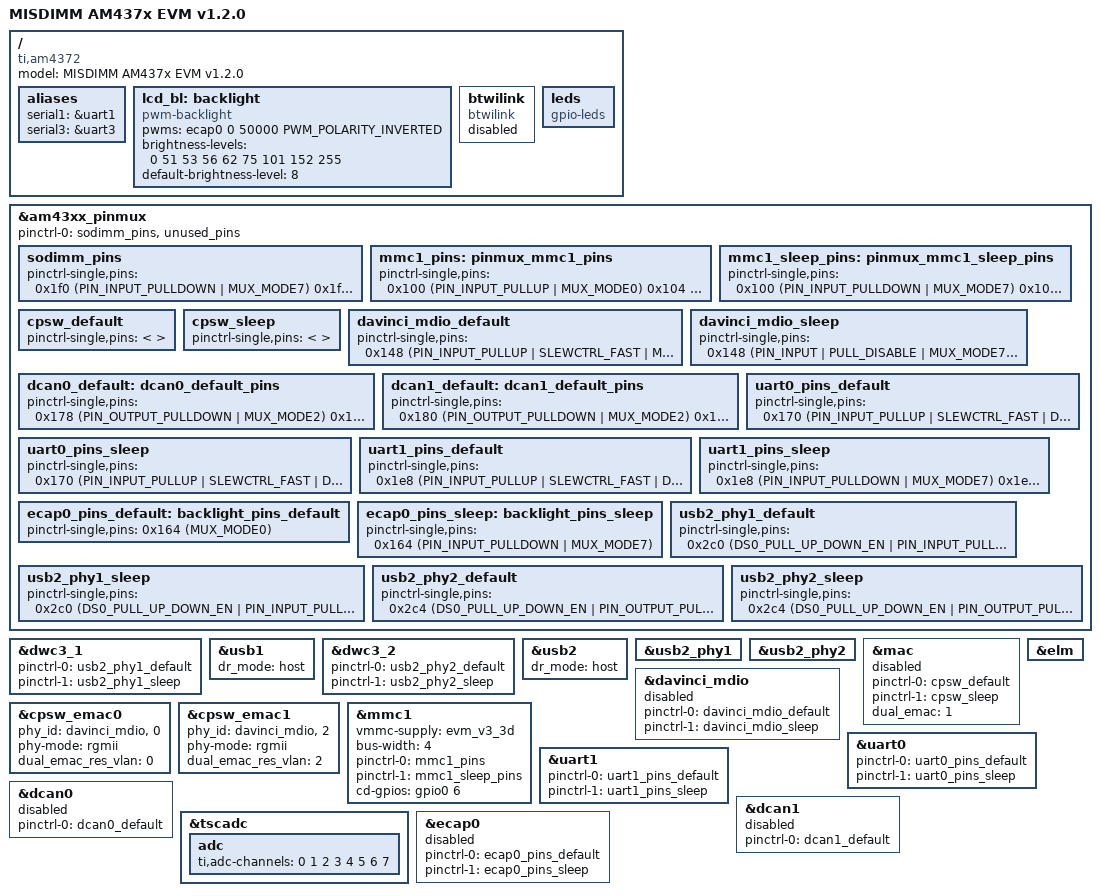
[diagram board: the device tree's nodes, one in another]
/*
 * MIS www.mistec.de SO-DIMM System on Module Evalboard with TI am437x
 * Copyright (C) 2015 - http://www.mistec.de Robert Woerle
 * 
 * Copied from arch/arm/boot/dts/am437x-gp-evm.dts which has
 * Copyright (C) 2013 Texas Instruments Incorporated - http://www.ti.com/
 * 
 * This program is free software; you can redistribute it and/or modify
 * it under the terms of the GNU General Public License version 2 as
 * published by the Free Software Foundation.
 */

/* AM437x SOM EVM Mistec */

/dts-v1/;

#include "am437x-misdimm.dtsi"
#include <dt-bindings/pinctrl/am43xx.h>
#include <dt-bindings/pwm/pwm.h>
#include <dt-bindings/interrupt-controller/irq.h>

/ {
	model = "MISDIMM AM437x EVM v1.2.0";
	compatible = "ti,am4372","ti,am43";

	aliases {
		serial1 = &uart1;
		serial3 = &uart3;
	};

	lcd_bl: backlight {
		compatible = "pwm-backlight";
		pwms = <&ecap0 0 50000 PWM_POLARITY_INVERTED>;
		brightness-levels = <0 51 53 56 62 75 101 152 255>;
		default-brightness-level = <8>;
	};

 	btwilink {
		status = "disabled";
 		compatible = "btwilink";
 	};

	leds {
		compatible = "gpio-leds";

		/* 0x274 P600_138 C24 xdma_event_intr1.gpio0_20 */
/*		led_cpu0 {
			label = "misdimm-evm_usr0";
			gpios = <&gpio0 20 GPIO_ACTIVE_HIGH>;
			linux,default-trigger = "cpu0";
		};*/

		/*0x238 P600_140 D25 gpio5_8.gpio5_8 */
/*		led_mmc0 {
			label = "misdimm-evm_usr1";
			gpios = <&gpio5 8 GPIO_ACTIVE_HIGH>;
			linux,default-trigger = "mmc0";
		};*/

		/* 0x23c P600_142 F24 gpio5_9.gpio5_9 */
/*		led_mmc1 {
			label = "misdimm-evm_usr2";
			gpios = <&gpio5 9 GPIO_ACTIVE_HIGH>;
			linux,default-trigger = "mmc1";
		};*/
	};
};

&am43xx_pinmux {
	pinctrl-names = "default";
	pinctrl-0 = <&sodimm_pins &unused_pins>;


	sodimm_pins: sodimm_pins {
		pinctrl-single,pins = <

			/* ClassName ADC01 */
			/* P600_25 AA12 ADC0_AIN0 */
			/* P600_27 Y12  ADC0_AIN1 */
			/* P600_29 Y13  ADC0_AIN2 */
			/* P600_31 AA13 ADC0_AIN3 */
			/* P600_33 AB13 ADC0_AIN4 */
			/* P600_35 AC13 ADC0_AIN5 */
			/* P600_37 AD13 ADC0_AIN6 */
			/* P600_39 AE13 ADC0_AIN7 */

			/* P600_26 AC16 ADC1_AIN0 */
			/* P600_28 AB16 ADC1_AIN1 */
			/* P600_30 AA16 ADC1_AIN2 */
			/* P600_32 AB15 ADC1_AIN3 */
			/* P600_34 AA15 ADC1_AIN4 */
			/* P600_36 Y15  ADC1_AIN5 */
			/* P600_38 AE16 ADC1_AIN6 */
			/* P600_40 AD16 ADC1_AIN7 */


			/* ClassName: UART0123 */
			0x1f0 (PIN_INPUT_PULLDOWN | MUX_MODE7) /* P600_50 AD21 cam1_data2.gpio4_16 */
			0x1f4 (PIN_INPUT_PULLDOWN | MUX_MODE7) /* P600_48 AE22 cam1_data3.gpio4_17 */
			0x1f8 (PIN_INPUT_PULLDOWN | MUX_MODE7) /* P600_43 AD22 cam1_data4.gpio4_18 */
			0x1fc (PIN_INPUT_PULLDOWN | MUX_MODE7) /* P600_45 AE23 cam1_data5.gpio4_19 */
			0x200 (PIN_INPUT_PULLDOWN | MUX_MODE7) /* P600_49 AD23 cam1_data6.gpio4_20 */
			0x204 (PIN_INPUT_PULLDOWN | MUX_MODE7) /* P600_47 AE24 cam1_data7.gpio4_21 */

			0x228 (PIN_INPUT_PULLDOWN | MUX_MODE7)	/* P600_55 H25 uart3_rxd.uart3_rxd */
			0x22c (PIN_INPUT_PULLDOWN | MUX_MODE7)	/* P600_53 H24 uart3_txd.uart3_txd */
			0x230 (PIN_INPUT_PULLDOWN | MUX_MODE7)	/* P600_59 H22 uart3_ctsn.uart3_ctsn */
			0x234 (PIN_INPUT_PULLDOWN | MUX_MODE7)	/* P600_57 K24 uart3_rtsn.uart3_rtsn */


			/* ClassName:LCD */
			0x0a0 (PIN_OUTPUT_PULLDOWN | MUX_MODE5) /* P600_77  B22 dss_data0.gpio2_6 */
			0x0a4 (PIN_INPUT_PULLDOWN | MUX_MODE7) /* P600_78  A21 dss_data1.gpio2_7 */
			0x0a8 (PIN_INPUT_PULLDOWN | MUX_MODE7) /* P600_79  B21 dss_data2.gpio2_8 */
			0x0ac (PIN_INPUT_PULLDOWN | MUX_MODE7) /* P600_80  C21 dss_data3.gpio2_9 */
			0x0b0 (PIN_INPUT_PULLDOWN | MUX_MODE7) /* P600_81  A20 dss_data4.gpio2_10 */
			0x0b4 (PIN_INPUT_PULLDOWN | MUX_MODE7) /* P600_82  B20 dss_data5.gpio2_11 */
			0x0b8 (PIN_INPUT_PULLDOWN | MUX_MODE7) /* P600_83  C20 dss_data6.gpio2_12 */
			0x0bc (PIN_INPUT_PULLDOWN | MUX_MODE7) /* P600_84  E19 dss_data7.gpio2_13 */
			0x0c0 (PIN_INPUT_PULLDOWN | MUX_MODE7) /* P600_85  A19 dss_data8.gpio2_14 */
			0x0c4 (PIN_INPUT_PULLDOWN | MUX_MODE7) /* P600_86  B19 dss_data9.gpio2_15 */
			0x0c8 (PIN_INPUT_PULLDOWN | MUX_MODE7) /* P600_87  A18 dss_data10.gpio2_16 */
			0x0cc (PIN_INPUT_PULLDOWN | MUX_MODE7) /* P600_88  B18 dss_data11.gpio2_17 */
			0x0d0 (PIN_INPUT_PULLDOWN | MUX_MODE7) /* P600_89  C19 dss_data12.gpio0_8 */
			0x0d4 (PIN_INPUT_PULLDOWN | MUX_MODE7) /* P600_90  D19 dss_data13.gpio0_9 */
			0x0d8 (PIN_INPUT_PULLDOWN | MUX_MODE7) /* P600_91  C17 dss_data14.gpio0_10 */
			0x0dc (PIN_INPUT_PULLDOWN | MUX_MODE7) /* P600_92  D17 dss_data15.gpio0_11 */

			0x0e0 (PIN_INPUT_PULLDOWN | MUX_MODE7) /* P600_74  B23 dss_vsync.gpio2_22 */
			0x0e4 (PIN_INPUT_PULLDOWN | MUX_MODE7) /* P600_75  A23 dss_hsync.gpio2_23 */
			0x0e8 (PIN_INPUT_PULLDOWN | MUX_MODE7) /* P600_76  A22 dss_pclk.gpio2_24 */
			0x0ec (PIN_INPUT_PULLDOWN | MUX_MODE7) /* P600_73  A24 dss_acbias.gpio2_25 */

			0x148 (PIN_INPUT | PULL_DISABLE | MUX_MODE7) /* P600_103 + P600_137 A17 mdio_data.gpio0_0 */
			0x14c (PIN_INPUT | PULL_DISABLE | MUX_MODE7) /* P600_105 + P600_139 B17 mdio_clk.gpio0_1 */

			0x1b0 (PIN_INPUT_PULLDOWN | MUX_MODE7) /* P600_100 AE17 cam0_hd.gpio4_0 */
			0x1b4 (PIN_INPUT_PULLDOWN | MUX_MODE7) /* P600_99  AD18 cam0_vd.gio4_1 */
			0x1b8 (PIN_INPUT_PULLDOWN | MUX_MODE7) /* P600_98  AC18 cam0_field.gpio4_2 */
			0x1bc (PIN_INPUT_PULLDOWN | MUX_MODE7) /* P600_97  AD17 cam0_wen.gpio4_3 */
			0x1c0 (PIN_INPUT_PULLDOWN | MUX_MODE7) /* P600_96  AC20 can0_pclk.gpio4_4 */
			0x1c4 (PIN_INPUT_PULLDOWN | MUX_MODE7) /* P600_95  AB19 cam0_data8.gpio4_5 */
			0x1c8 (PIN_INPUT_PULLDOWN | MUX_MODE7) /* P600_94  AA19 cam0_data9.gpio4_6 */
			0x1cc (PIN_INPUT_PULLDOWN | MUX_MODE7) /* P600_93  AC24 cam1_data9.gpio4_7 */

			/* ClassName:SPI */
			0x190 (PIN_INPUT_PULLDOWN | MUX_MODE7) /* P600_106 N24  mcasp0_aclkx.gpio3_14 */
			0x194 (PIN_INPUT_PULLDOWN | MUX_MODE7) /* P600_108 N22  mcasp0_fsx.gpio3_15 */
			0x198 (PIN_INPUT_PULLDOWN | MUX_MODE7) /* P600_110 H23  mcasp0_axr0.gpio3_16 */
			0x19c (PIN_INPUT_PULLDOWN | MUX_MODE7) /* P600_112 M24  mcasp0_ahclkr.gpio3_17 */
			0x1d8 (PIN_INPUT_PULLDOWN | MUX_MODE7) /* P600_114 AC23 cam1_vd.gpio4_10 */
			0x1dc (PIN_INPUT_PULLDOWN | MUX_MODE7) /* P600_116 AE21 cam1_pclk.gpio4_11 */


			/* ClassName:AUDIO */
			0x144 (PIN_INPUT_PULLDOWN | MUX_MODE7) /* P600_120 A16  rmii1_ref_clk.gpio0_29 */
			0x108 (PIN_INPUT_PULLDOWN | MUX_MODE7) /* P600_122 D16  mii1_col.gpio3_0 */
			0x10c (PIN_INPUT_PULLDOWN | MUX_MODE7) /* P600_126 B14  mii1_crs.gpio3_1 */
			0x110 (PIN_INPUT_PULLDOWN | MUX_MODE7) /* P600_128 B13  mii1_rx_er.gpio3_2 */
			0x270 (PIN_INPUT_PULLDOWN | MUX_MODE7) /* P600_124 D24  xdma_event_intr0.gpio0_19 */


			/* ClassName:GPIOS */
			0x070 (PIN_INPUT_PULLDOWN | MUX_MODE7) /* P600_178 A2   gpmc_wait0.gpio0_30 */
			0x074 (PIN_INPUT_PULLDOWN | MUX_MODE7) /* P600_150 B3   gpmc_wpn.gpio0_31 */
			0x078 (PIN_INPUT_PULLDOWN | MUX_MODE7) /* P600_152 A3   gpmc_be1n.gpio1_28 */
			0x07c (PIN_INPUT_PULLDOWN | MUX_MODE7) /* P600_146 A8   gpmc_csn0.gpio1_29 */
			0x090 (PIN_INPUT_PULLDOWN | MUX_MODE7) /* P600_144 A9   gpmc_advn_ale.gpio2_2 */
			0x09c (PIN_INPUT_PULLDOWN | MUX_MODE7) /* P600_156 C10  gpmc_be0n_cle.gpio2_5 */
			0x150 (PIN_INPUT_PULLDOWN | MUX_MODE7) /* P600_160 P23  spi0_sclk.gpio0_2 */
			0x154 (PIN_INPUT_PULLDOWN | MUX_MODE7) /* P600_154 T22  spi0_d0.gpio0_3 */
			0x1a0 (PIN_INPUT_PULLDOWN | MUX_MODE7) /* P600_180 L23  mcasp0_aclkr.gpio3_18 */
			0x1a4 (PIN_INPUT_PULLDOWN | MUX_MODE7) /* P600_176 K23  mcasp0_fsr.gpio3_19 */
			0x1ac (PIN_INPUT_PULLDOWN | MUX_MODE7) /* P600_162 L24  mcasp0_ahclkx.gpio3_21 */
			0x1e0 (PIN_INPUT_PULLDOWN | MUX_MODE7) /* P600_184 AC25 cam1_field.gpio4_12 */
			0x1e4 (PIN_INPUT_PULLDOWN | MUX_MODE7) /* P600_182 AB25 cam1_wen.gpio4_13 */
			0x218 (PIN_INPUT_PULLDOWN | MUX_MODE7) /* P600_148 AE19 cam0_data4.gpio4_26 */
			0x220 (PIN_INPUT_PULLDOWN | MUX_MODE7) /* P600_174 AE20 cam0_data6.gpio4_28 */
			0x224 (PIN_INPUT_PULLDOWN | MUX_MODE7) /* P600_186 AD20 cam0_data7.gpio4_29 */
			0x240 (PIN_INPUT_PULLDOWN | MUX_MODE7) /* P600_170 G20  gpio5_10.gpio5_10 */
			0x250 (PIN_INPUT_PULLDOWN | MUX_MODE7) /* P600_172 P25  spi4_sclk.gpio5_4 */
			0x258 (PIN_INPUT_PULLDOWN | MUX_MODE7) /* P600_164 P24  spi4_d1.gpio5_6 */
			0x264 (PIN_INPUT_PULLDOWN | MUX_MODE7) /* P600_158 P22  spi2_d0.gpio3_22 */
			0x278 (PIN_INPUT_PULLDOWN | MUX_MODE7) /* P600_166 H20  clkreq.gpio0_24 */

			/* ClassName:ETH1 Slave 1 */
			0x114 (PIN_INPUT_PULLDOWN | MUX_MODE7)			/* P600_119 A13 mii1_txen.gpio3_3 */
			0x118 (PIN_INPUT_PULLDOWN | MUX_MODE7)			/* P600_109 A15 mii1_rxdv.gpio3_4 */
			0x11c (PIN_INPUT_PULLDOWN | MUX_MODE7)			/* P600_123 C16 mii1_txd3.gpio0_16 */
			0x120 (PIN_INPUT_PULLDOWN | MUX_MODE7)			/* P600_125 C13 mii1_txd2.gpio0_17 */
			0x124 (PIN_INPUT_PULLDOWN | MUX_MODE7)			/* P600_127 A14 mii1_txd1.gpio0_21 */
			0x128 (PIN_INPUT_PULLDOWN | MUX_MODE7)			/* P600_129 B15 mii1_txd0.gpio0_28 */
			0x12c (PIN_INPUT_PULLDOWN | MUX_MODE7)			/* P600_121 D14 mii1_txclk.gpio3_9 */
			0x130 (PIN_INPUT_PULLDOWN | MUX_MODE7)			/* P600_107 D13 mii1_rxclk.gpio3_10 */
			0x134 (PIN_INPUT | PULL_DISABLE | MUX_MODE7)	/* P600_117 C14 mii1_rxd3.gpio2_18 */
			0x138 (PIN_INPUT | PULL_DISABLE | MUX_MODE7)	/* P600_115 E16 mii1_rxd2.gpio2_19 */
			0x13c (PIN_INPUT | PULL_DISABLE | MUX_MODE7)	/* P600_113 B16 mii1_rxd1.gpio2_20 */
			0x140 (PIN_INPUT | PULL_DISABLE | MUX_MODE7)	/* P600_111 F17 mii1_rxd0.gpio2_21 */
			0x16C (PIN_INPUT_PULLDOWN | MUX_MODE7)			/* P600_58 J25 uart0_rtsn.gpio1_9 */

			/* ClassName:ETH2 Slave 2 */
			0x040 (PIN_INPUT_PULLDOWN | MUX_MODE7)			/* P600_153 C3 gpmc_a0.gpio1_16 */
			0x044 (PIN_INPUT_PULLDOWN | MUX_MODE7)			/* P600_143 C5 gpmc_a1.gpio1_17 */
			0x048 (PIN_INPUT_PULLDOWN | MUX_MODE7)			/* P600_157 C6 gpmc_a2.gpio1_18 */
			0x04c (PIN_INPUT_PULLDOWN | MUX_MODE7)			/* P600_159 A4 gpmc_a3.gpio1_19 */
			0x050 (PIN_INPUT_PULLDOWN | MUX_MODE7)			/* P600_161 D7 gpmc_a4.gpio1_20 */
			0x054 (PIN_INPUT_PULLDOWN | MUX_MODE7)			/* P600_163 E7 gpmc_a5.gpio1_21 */
			0x058 (PIN_INPUT_PULLDOWN | MUX_MODE7)			/* P600_155 E8 gpmc_a6.gpio1_22 */
			0x05c (PIN_INPUT_PULLDOWN | MUX_MODE7)			/* P600_141 F6 gpmc_a7.gpio1_23 */
			0x060 (PIN_INPUT | PULL_DISABLE | MUX_MODE7)	/* P600_151 F7 gpmc_a8.gpio1_24 */
			0x064 (PIN_INPUT | PULL_DISABLE | MUX_MODE7)	/* P600_149 B4 gpmc_a9.gpio1_25 */
			0x068 (PIN_INPUT | PULL_DISABLE | MUX_MODE7)	/* P600_147 G8 gpmc_a10.gpio1_26 */
			0x06c (PIN_INPUT | PULL_DISABLE | MUX_MODE7)	/* P600_145 D8 gpmc_a11.gpio1_27 */
			0x168 (PIN_INPUT_PULLDOWN | MUX_MODE7)			/* P600_60 L25 uart0_ctsn.gpio1_8 */

			/* ClassName:USB01*/
		>;
	};

	mmc1_pins: pinmux_mmc1_pins {
		pinctrl-single,pins = <
			0x100 (PIN_INPUT_PULLUP | MUX_MODE0) /* mmc0_clk.mmc0_clk */
			0x104 (PIN_INPUT_PULLUP | MUX_MODE0) /* mmc0_cmd.mmc0_cmd */
			0x0f0 (PIN_INPUT_PULLUP | MUX_MODE0) /* mmc0_dat0.mmc0_dat0 */
			0x0f4 (PIN_INPUT_PULLUP | MUX_MODE0) /* mmc0_dat1.mmc0_dat1 */
			0x0f8 (PIN_INPUT_PULLUP | MUX_MODE0) /* mmc0_dat2.mmc0_dat2 */
			0x0fc (PIN_INPUT_PULLUP | MUX_MODE0) /* mmc0_dat3.mmc0_dat3 */
			0x160 (PIN_INPUT_PULLDOWN | MUX_MODE7) /* spi0_cs1.mmc0_sdcd HACK to card detec both */
		>;
	};

	mmc1_sleep_pins: pinmux_mmc1_sleep_pins {
		pinctrl-single,pins = <
			0x100 (PIN_INPUT_PULLDOWN | MUX_MODE7)
			0x104 (PIN_INPUT | PULL_DISABLE | MUX_MODE7)
			0x0f0 (PIN_INPUT | PULL_DISABLE | MUX_MODE7)
			0x0f4 (PIN_INPUT | PULL_DISABLE | MUX_MODE7)
			0x0f8 (PIN_INPUT | PULL_DISABLE | MUX_MODE7)
			0x0fc (PIN_INPUT | PULL_DISABLE | MUX_MODE7)
		>;
	};

	cpsw_default: cpsw_default {
		pinctrl-single,pins = <
			/* ClassName:ETH1 Slave 1 */
		>;
	};

	cpsw_sleep: cpsw_sleep {
		pinctrl-single,pins = <
			/* ClassName:ETH1 Slave 1 reset value */
		>;
	};

	davinci_mdio_default: davinci_mdio_default {
		pinctrl-single,pins = <
			/* ClassName:ETH1  MDIO */
			0x148 (PIN_INPUT_PULLUP | SLEWCTRL_FAST | MUX_MODE0) /* P600_103 + P600_137 A17 mdio_data.mdio_data */
			0x14c (PIN_OUTPUT_PULLUP | MUX_MODE0)				 /* P600_105 + P600_139 B17 mdio_clk.mdio_clk */
		>;
	};

	davinci_mdio_sleep: davinci_mdio_sleep {
		pinctrl-single,pins = <
			/* ClassName:ETH1 MDIO reset value */
			0x148 (PIN_INPUT | PULL_DISABLE | MUX_MODE7) /* P600_103 + P600_137 A17 mdio_data.gpio0_0 */
			0x14c (PIN_INPUT | PULL_DISABLE | MUX_MODE7) /* P600_105 + P600_139 B17 mdio_clk.gpio0_1 */
		>;
	};

	dcan0_default: dcan0_default_pins {
		pinctrl-single,pins = <
			/* ClassName:CAN */
			0x178 (PIN_OUTPUT_PULLDOWN | MUX_MODE2) /* P600_63 K22 uart1_ctsn.d_can0_tx */
			0x17c (PIN_INPUT_PULLUP | MUX_MODE2) 	/* P600_65 L22 uart1_rtsn.d_can0_rx */
		>;
	};

	dcan1_default: dcan1_default_pins {
		pinctrl-single,pins = <
			/* ClassName:CAN */
			0x180 (PIN_OUTPUT_PULLDOWN | MUX_MODE2) /* P600_67 K21 uart1_rxd.d_can1_tx */
			0x184 (PIN_INPUT_PULLUP | MUX_MODE2) 	/* P600_69 L21 uart1_txd.d_can1_rx */
		>;
	};

	uart0_pins_default: uart0_pins_default {
		pinctrl-single,pins = <
			0x170 (PIN_INPUT_PULLUP | SLEWCTRL_FAST | DS0_PULL_UP_DOWN_EN | MUX_MODE0) /* P600_56 K25 uart0_rxd.uart0_rxd */
			0x174 (PIN_INPUT | PULL_DISABLE | SLEWCTRL_FAST | DS0_PULL_UP_DOWN_EN | MUX_MODE0) /* P600_54 J24 uart0_txd.uart0_txd */
		>;
	};

	uart0_pins_sleep: uart0_pins_sleep {
		pinctrl-single,pins = <
			0x170 (PIN_INPUT_PULLUP | SLEWCTRL_FAST | DS0_PULL_UP_DOWN_EN | MUX_MODE0) /* P600_56 K25 uart0_rxd.uart0_rxd */
			0x174 (PIN_INPUT_PULLDOWN | SLEWCTRL_FAST | DS0_PULL_UP_DOWN_EN | MUX_MODE0) /* P600_54 J24 uart0_txd.uart0_txd */
		>;
	};

	uart1_pins_default: uart1_pins_default {
		pinctrl-single,pins = <
			0x1e8 (PIN_INPUT_PULLUP | SLEWCTRL_FAST | DS0_PULL_UP_DOWN_EN | MUX_MODE1) /* P600_44 AB20 cam1_data0.uart1_rxd */
			0x1ec (PIN_INPUT | PULL_DISABLE | SLEWCTRL_FAST | DS0_PULL_UP_DOWN_EN | MUX_MODE1) /* P600_46 AC21 cam1_data1.uart1_txd */
		>;
	};

	uart1_pins_sleep: uart1_pins_sleep {
		pinctrl-single,pins = <
			0x1e8 (PIN_INPUT_PULLDOWN | MUX_MODE7) /* P600_44 AB20 cam1_data0.gpio4_14 */
			0x1ec (PIN_INPUT_PULLDOWN | MUX_MODE7) /* P600_46 AC21 cam1_data1.gpio4_15 */
		>;
	};

	ecap0_pins_default: backlight_pins_default {
		pinctrl-single,pins = <
			0x164 (MUX_MODE0) /* P600_104 G24 ecap0_pwm0_out.ecap0_pwm0_out*/
		>;
	};

	ecap0_pins_sleep: backlight_pins_sleep {
		pinctrl-single,pins = <
			0x164 (PIN_INPUT_PULLDOWN | MUX_MODE7)
		>;
	};

	usb2_phy1_default: usb2_phy1_default {
		pinctrl-single,pins = <
			0x2c0 (DS0_PULL_UP_DOWN_EN | PIN_INPUT_PULLDOWN | MUX_MODE0)
		>;
	};

	usb2_phy1_sleep: usb2_phy1_sleep {
		pinctrl-single,pins = <
			0x2c0 (DS0_PULL_UP_DOWN_EN | PIN_INPUT_PULLDOWN | MUX_MODE7)
		>;
	};

	usb2_phy2_default: usb2_phy2_default {
		pinctrl-single,pins = <
			0x2c4 (DS0_PULL_UP_DOWN_EN | PIN_OUTPUT_PULLDOWN | MUX_MODE0)	/* P600_201 F25   usb1_drvvbus.usb1_drvvbus */
		>;
	};

	usb2_phy2_sleep: usb2_phy2_sleep {
		pinctrl-single,pins = <
			0x2c4 (DS0_PULL_UP_DOWN_EN | PIN_OUTPUT_PULLDOWN | MUX_MODE7)	/* P600_201 F25   usb1_drvvbus.gpio3_13 */
		>;
	};

};

&dwc3_1 {
	pinctrl-names = "default", "sleep";
	pinctrl-0 = <&usb2_phy1_default>;
	pinctrl-1 = <&usb2_phy1_sleep>;

};

&usb1 {
	dr_mode = "host";
	status = "okay";
};

&dwc3_2 {
	pinctrl-names = "default", "sleep";
	pinctrl-0 = <&usb2_phy2_default>;
	pinctrl-1 = <&usb2_phy2_sleep>;
};

&usb2 {
	dr_mode = "host";
	status = "okay";
};

&usb2_phy1 {
	status = "okay";
};

&usb2_phy2 {
	status = "okay";
};

&mac {
	pinctrl-names = "default", "sleep";
	pinctrl-0 = <&cpsw_default>;
	pinctrl-1 = <&cpsw_sleep>;
	status = "disabled";
	dual_emac = <1>;
};

&davinci_mdio {
	pinctrl-names = "default", "sleep";
	pinctrl-0 = <&davinci_mdio_default>;
	pinctrl-1 = <&davinci_mdio_sleep>;
	status = "disabled";
};

&cpsw_emac0 {
	phy_id = <&davinci_mdio>, <0>;
	phy-mode = "rgmii";
	dual_emac_res_vlan = <0>;
};

&cpsw_emac1 {
	phy_id = <&davinci_mdio>, <2>;
	phy-mode = "rgmii";
	dual_emac_res_vlan = <2>;
};

&elm {
	status = "okay";
};

&mmc1 {
	status = "okay";
	vmmc-supply = <&evm_v3_3d>;
	bus-width = <4>;
	pinctrl-names = "default", "sleep";
	pinctrl-0 = <&mmc1_pins>;
	pinctrl-1 = <&mmc1_sleep_pins>;
	cd-gpios = <&gpio0 6 GPIO_ACTIVE_HIGH>;
};

&uart0 {
	status = "okay";
	pinctrl-names = "default", "sleep";
	pinctrl-0 = <&uart0_pins_default>;
	pinctrl-1 = <&uart0_pins_sleep>;
};

&uart1 {
	status = "okay";
	pinctrl-names = "default", "sleep";
	pinctrl-0 = <&uart1_pins_default>;
	pinctrl-1 = <&uart1_pins_sleep>;
};

&dcan0 {
	pinctrl-names = "default";
	pinctrl-0 = <&dcan0_default>;
	status = "disabled";
};

&dcan1 {
	pinctrl-names = "default";
	pinctrl-0 = <&dcan1_default>;
	status = "disabled";
};

&tscadc {
	status = "okay";
	adc {
		ti,adc-channels = <0 1 2 3 4 5 6 7>;
	};
};

&ecap0 {
	status = "disabled";
	pinctrl-names = "default", "sleep";
	pinctrl-0 = <&ecap0_pins_default>;
	pinctrl-1 = <&ecap0_pins_sleep>;
};
